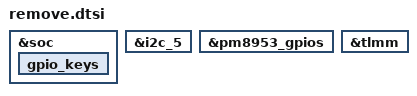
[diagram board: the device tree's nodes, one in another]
&soc {
	gpio_keys {
		/delete-node/ camera_focus;
		/delete-node/ camera_snapshot;
	};

	/delete-node/ hbtp;
};

&i2c_5 {
	/delete-node/ nq@28;
};

&pm8953_gpios {
	/delete-node/ nfc_clk;
};

&tlmm {
	/delete-node/ fpc_reset_int;
	/delete-node/ nfc;
};
